# nrf54l15_application register map
Vendor: Nordic Semiconductor; Series: nrf54l; File version: 1
CPU: CM33 r0p4, little endian, MPU, FPU, 3 interrupt priority bits, 270 interrupts, 4 SAU regions
Registers are 32-bit, read-write, reset 0x0 unless marked. A register's access mark holds for its fields unless they carry their own. Offsets are from the block's base; [hi:lo] are bit positions; lines under a group give offsets from that group; 'fields as' and 'values as' point back to an identical list.

## GLOBAL_GPIOHSPADCTRL_S — GPIO high-speed pad control
Base 0x50050400
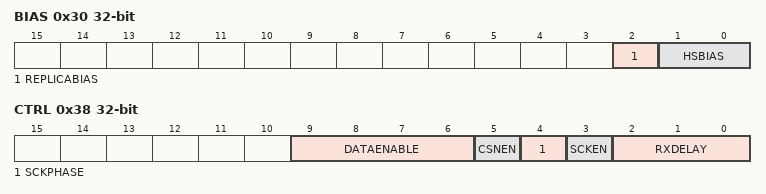
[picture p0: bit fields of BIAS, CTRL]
0x30 BIAS — Bias control
  [2] REPLICABIAS — Slew setting for replica clock (used by the VPR coprocessor for emulating a QSPI peripheral)
  [1:0] HSBIAS — Slew setting for high-speed pad (higher value is faster)
0x38 CTRL — Input sampling and buffering control (used by the VPR coprocessor for emulating a QSPI peripheral)
  [9:6] DATAENABLE — Enable delayed sampling
    0=Disabled (Delayed sampling is disabled); 15=Enabled (Delayed sampling is enabled)
  [5] CSNEN — Enable CSN synchronization of sampling
    0=Enabled (Delay chain is reset on active edge of CSN); 1=Disabled (Delay chain is not reset on active edge of CSN)
  [4] SCKPHASE
    0=Inverted (Invert SCK phase); 1=Non-inverted SCK phase
  [3] SCKEN — Enable SCK
    0=Disabled (Delay chain is reset and delayed sampling is disabled); 1=Enabled (Delay chain and delayed sampling is active)
  [2:0] RXDELAY — Delay selection

## GLOBAL_CTRLAP_NS — Control access port 0
Base 0x40052000
Same registers: GLOBAL_CTRLAP_S 0x50052000
0x100 EVENTS_RXREADY — RXSTATUS is changed to DataPending.
  [0] EVENTS_RXREADY
    0=NotGenerated (Event not generated); 1=Generated (Event generated)
0x104 EVENTS_TXDONE — TXSTATUS is changed to NoDataPending.
  [0] EVENTS_TXDONE
    values as EVENTS_RXREADY.EVENTS_RXREADY
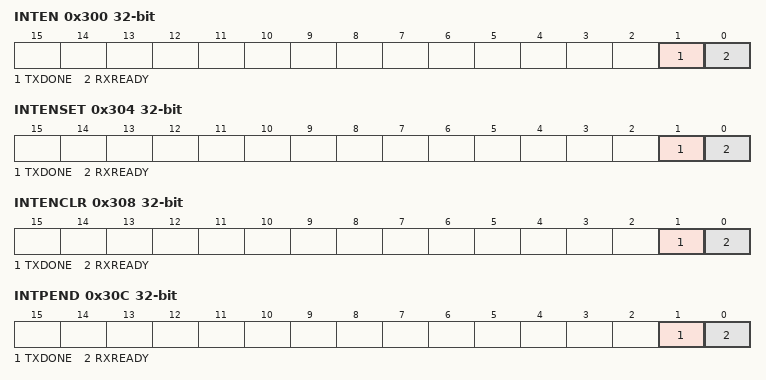
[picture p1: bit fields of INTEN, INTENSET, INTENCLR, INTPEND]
0x300 INTEN — Enable or disable interrupt
  [1] TXDONE — Enable or disable interrupt for event TXDONE
    0=Disabled; 1=Enabled
  [0] RXREADY — Enable or disable interrupt for event RXREADY
    0=Disabled; 1=Enabled
0x304 INTENSET — Enable interrupt
  [1] TXDONE write-1-sets — Write '1' to enable interrupt for event TXDONE
    on read: 0=Disabled (Read: Disabled); 1=Enabled (Read: Enabled) | on write: 1=Set (Enable)
  [0] RXREADY write-1-sets — Write '1' to enable interrupt for event RXREADY
    values as TXDONE
0x308 INTENCLR — Disable interrupt
  [1] TXDONE write-1-clears — Write '1' to disable interrupt for event TXDONE
    on read: 0=Disabled (Read: Disabled); 1=Enabled (Read: Enabled) | on write: 1=Clear (Disable)
  [0] RXREADY write-1-clears — Write '1' to disable interrupt for event RXREADY
    values as TXDONE
0x30C INTPEND ro — Pending interrupts
  [1] TXDONE — Read pending status of interrupt for event TXDONE
    on read: 0=NotPending (Read: Not pending); 1=Pending (Read: Pending)
  [0] RXREADY — Read pending status of interrupt for event RXREADY
    values as TXDONE
0x400 MAILBOX group — Unspecified
  0x00 RXDATA ro — Data sent from the debugger to the CPU.
    [31:0] RXDATA — Data received from debugger.
  0x04 RXSTATUS ro — Status to indicate if data sent from the debugger to the CPU has been read.
    [0] RXSTATUS — Status of data in register RXDATA.
      0=NoDataPending (No data is pending in register RXDATA.); 1=DataPending (Data is pending in register RXDATA.)
  0x80 TXDATA — Data sent from the CPU to the debugger.
    [31:0] TXDATA — Data sent to debugger.
  0x84 TXSTATUS ro — Status to indicate if data sent from the CPU to the debugger has been read.
    [0] TXSTATUS — Status of data in register TXDATA.
      0=NoDataPending (No data is pending in register TXDATA.); 1=DataPending (Data is pending in register TXDATA.)
0x500 ERASEPROTECT group — Unspecified
  0x00 LOCK rw-once — This register locks the ERASEPROTECT.DISABLE register from being written until next reset.
    [0] LOCK — Writing any value will lock the ERASEPROTECT.DISABLE register from being written until next reset.
      1=Locked (Register ERASEPROTECT.DISABLE is read-only.)
  0x04 DISABLE write-once — This register disables the ERASEPROTECT register and performs an ERASEALL operation.
    [31:0] KEY — The ERASEALL sequence is initiated if the value of the KEY fields are non-zero and the KEY fields match on both the CPU and debugger sides.
0x520 RESET wo — System reset request.
  [2:0] RESET — Reset request
    0=No reset is generated; 1=SoftReset (Perform a device soft reset); 2=HardReset (Perform a device hard reset); 4=PinReset (Perform a device pin reset)

## Notices in the file
Copyright (c) 2010 - 2025, Nordic Semiconductor ASA All rights reserved.
SPDX-License-Identifier: BSD-3-Clause
Redistribution and use in source and binary forms, with or without
modification, are permitted provided that the following conditions are met:
1. Redistributions of source code must retain the above copyright notice, this
list of conditions and the following disclaimer.
2. Redistributions in binary form must reproduce the above copyright
notice, this list of conditions and the following disclaimer in the
documentation and/or other materials provided with the distribution.
3. Neither the name of Nordic Semiconductor ASA nor the names of its
contributors may be used to endorse or promote products derived from this
software without specific prior written permission.
THIS SOFTWARE IS PROVIDED BY THE COPYRIGHT HOLDERS AND CONTRIBUTORS "AS IS"
AND ANY EXPRESS OR IMPLIED WARRANTIES, INCLUDING, BUT NOT LIMITED TO, THE
IMPLIED WARRANTIES OF MERCHANTABILITY, AND FITNESS FOR A PARTICULAR PURPOSE
ARE DISCLAIMED. IN NO EVENT SHALL NORDIC SEMICONDUCTOR ASA OR CONTRIBUTORS BE
LIABLE FOR ANY DIRECT, INDIRECT, INCIDENTAL, SPECIAL, EXEMPLARY, OR
CONSEQUENTIAL DAMAGES (INCLUDING, BUT NOT LIMITED TO, PROCUREMENT OF
SUBSTITUTE GOODS OR SERVICES; LOSS OF USE, DATA, OR PROFITS; OR BUSINESS
INTERRUPTION) HOWEVER CAUSED AND ON ANY THEORY OF LIABILITY, WHETHER IN
CONTRACT, STRICT LIABILITY, OR TORT (INCLUDING NEGLIGENCE OR OTHERWISE)
ARISING IN ANY WAY OUT OF THE USE OF THIS SOFTWARE, EVEN IF ADVISED OF THE
POSSIBILITY OF SUCH DAMAGE.
